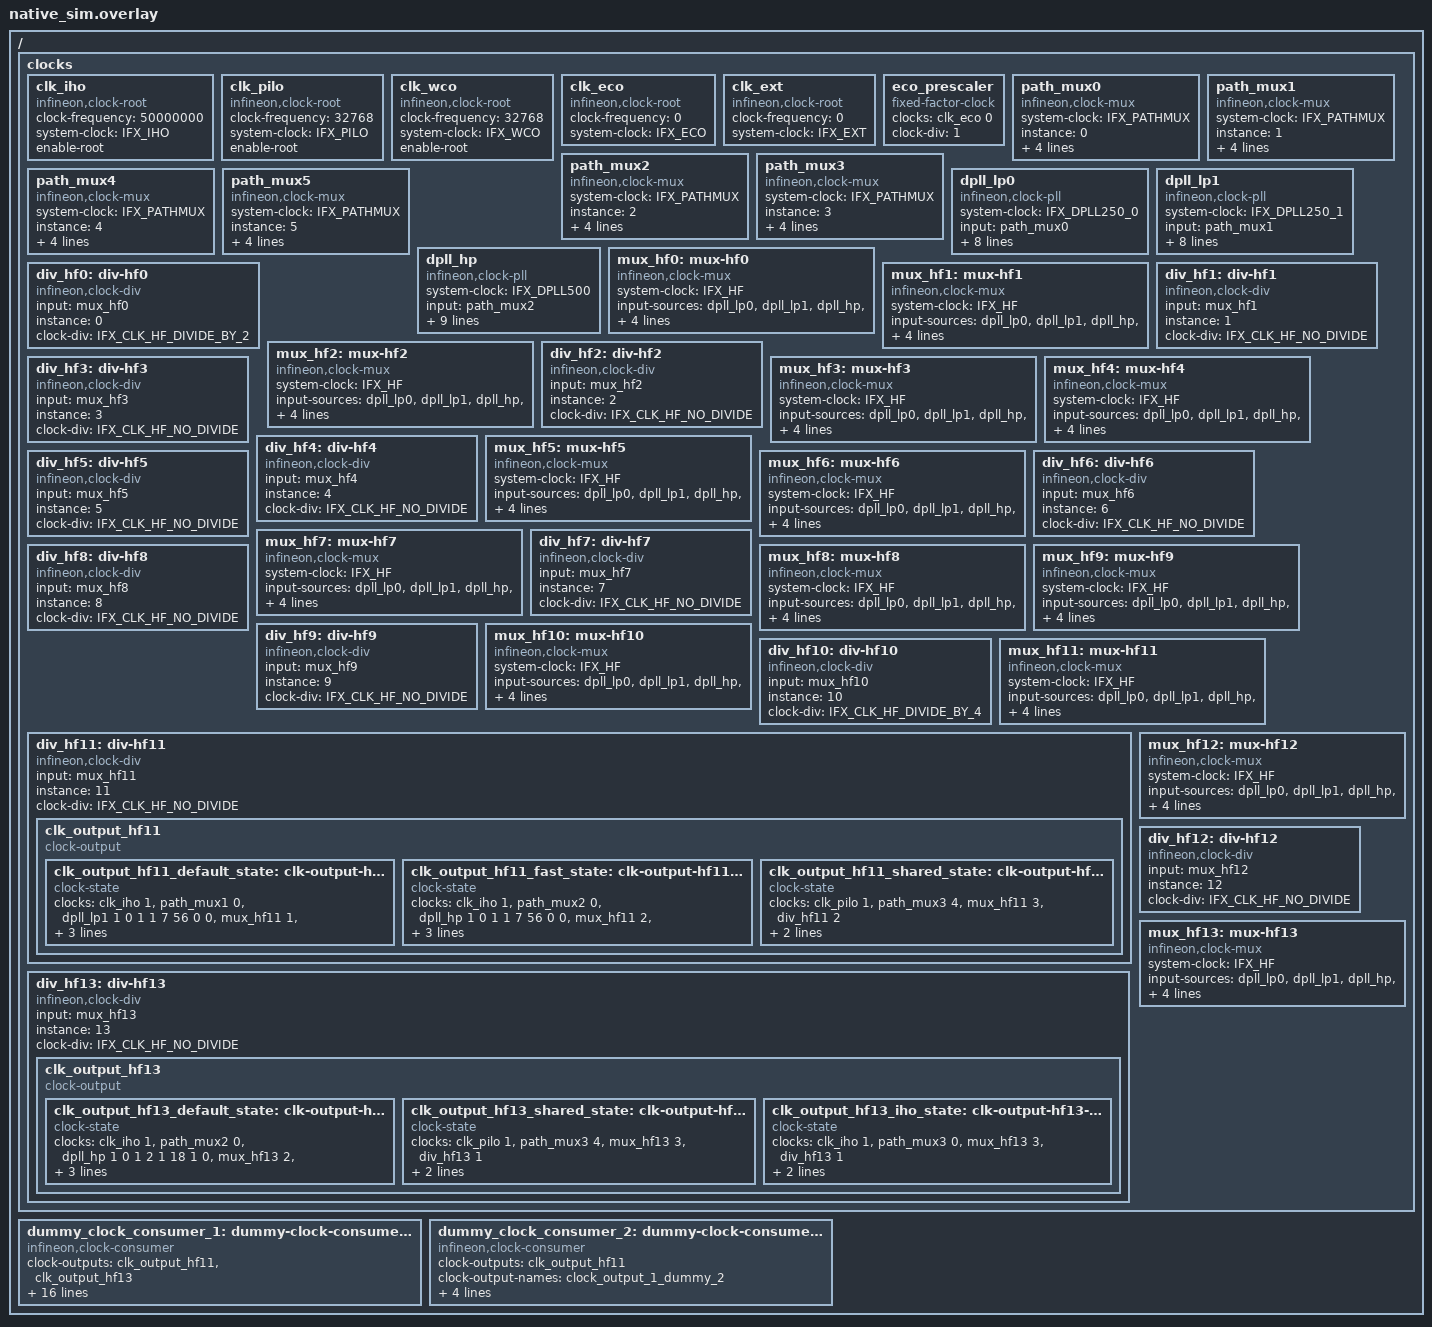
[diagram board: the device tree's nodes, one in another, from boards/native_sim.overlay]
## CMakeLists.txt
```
cmake_minimum_required(VERSION 3.20.0)
find_package(Zephyr REQUIRED HINTS $ENV{ZEPHYR_BASE})
project(pse84_m33_clock_management)

add_clock_management_header(include/infineon_clock_management_header.h)
zephyr_include_directories(include)

target_sources(app PRIVATE
    src/main.c
    drivers/infineon_clock_root.c
    drivers/infineon_clock_mux.c
    drivers/infineon_clock_pll.c
    drivers/infineon_clock_hf.c
    drivers/infineon_clock_div.c
    drivers/infineon_clock_consumer.c
)
```

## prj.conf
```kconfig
CONFIG_BUILD_OUTPUT_HEX=y
CONFIG_CLOCK_MANAGEMENT=y
CONFIG_CLOCK_MANAGEMENT_RUNTIME=y
CONFIG_NO_OPTIMIZATIONS=y
CONFIG_CLOCK_MANAGEMENT_SET_RATE=y
#CONFIG_INSTRUMENTATION_TRIGGER_FUNCTION="instrumentation_trigger"
#CONFIG_INSTRUMENTATION=y
#CONFIG_INSTRUMENTATION_MODE_CALLGRAPH=y
#CONFIG_INSTRUMENTATION_EXCLUDE_FILE_LIST="xip,bitmask,version,spi,i2c,adc,pwm,wdt,usb,mem,cy_crypto,cy_ble,cy_tcpwm,cy_adc,cy_dac,cy_smartio,cy_sdhc,cmsis,crypto,dma,cy_mpc,cy_ppc,cy_trigmux,qspi,bitarray"
#CONFIG_INSTRUMENTATION_EXCLUDE_FILE_LIST="isr_wrapper,xip,bitmask,version,spi,i2c,adc,pwm,wdt,usb,mem,cy_crypto,cy_ble,cy_tcpwm,cy_adc,cy_dac,cy_smartio,cy_sdhc,cmsis,crypto,dma,cy_mpc,cy_ppc,cy_trigmux,qspi,assert,bitarray"

#CONFIG_INSTRUMENTATION_EXCLUDE_FUNCTION_LIST="pm_device_runtime_is_enabled,device_is_ready,pm_device_is_busy,pm_device_wakeup_is_enabled,pm_device_action_run,main,k_busy_wait,sys_clock_elapsed,any_cpu_announcing,this_cpu_announcin,runq_bes,next_up,update_cache,sys_clock_cycle_get_32,arch_k_cycle_get_32,k_cycle_get_3,arch_irq_lock,arch_irq_unlock,timeout"
#CONFIG_INSTRUMENTATION_MODE_CALLGRAPH_TRACE_BUFFER_SIZE=32768
#CONFIG_INSTRUMENTATION_MODE_CALLGRAPH_BUFFER_OVERWRITE=y
#CONFIG_INSTRUMENTATION_STOPPER_FUNCTION="instrumentation_stopper"
#CONFIG_INSTRUMENTATION_DYNAMIC_TRIGGER=n
```

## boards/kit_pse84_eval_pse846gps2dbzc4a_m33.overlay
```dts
&clk_iho {
	#clock-cells = <1>;
	compatible = "infineon,clock-root";
};
&path_mux1 {
	#clock-cells = <1>;
	compatible = "infineon,clock-mux";
	input-sources = <&clk_iho>;
	/delete-property/ source-path;
};
&dpll_lp1 {
	#clock-cells = <7>;
	compatible = "infineon,clock-pll";
	clock-frequency = < 0x17d78400 >;
	feedback-div = < 0x38 >;
	output-div = < 0x1 >;
	fraction-div = < 0x0 >;
	input = <&path_mux1>;
	dco-mode-enable;
};
&clk_hf10 {
	#clock-cells = <2>;
	input-sources = <&dpll_lp1>;
	compatible = "infineon,clock-hf";
	clock-div = < 0x3 >;
	/delete-property/ source-path;
	clk_output_hf10: clk_output_hf10 {
		#clock-cells = <0>;
		compatible = "clock-output";
		clk_output_hf10_default_state: clk_output_hf10_default_state {
			compatible = "clock-state";
			clocks = <&clk_iho 0x2faf080>, <&path_mux1 0>, <&dpll_lp1 1 0 56 7 1 1 0>, <&clk_hf10 0 3>;
		};
	};
};
&scb2 {
	clock-outputs = <&clk_output_hf10>;
	clock-output-names = "uart_clk";
	clock-request-0 = <&clk_output_hf10_default_state>;
	clock-request-names = "default";
};
&scb4 {
	clock-outputs = <&clk_output_hf10>;
	clock-output-names = "uart_clk";
	clock-request-0 = <&clk_output_hf10_default_state>;
	clock-request-names = "default";
	status = "disabled";
};
```

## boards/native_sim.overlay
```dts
/ {
	/* Clock tree 1/3: roots and path muxes (the 3 /clocks blocks merge). */
	clocks {
		/*
		 * Root oscillator sources (TRM 21.3).
		 */

		/*
		 * Default clock source fixed frequency of 50MHz.
		 */
		clk_iho: clk_iho {
			compatible = "infineon,clock-root";
			#clock-cells = <1>;
			clock-frequency = <50000000>;
			system-clock = <IFX_IHO>;
			enable-root;
			status = "okay";
		};

		/*
		 * Precision-Low Power clock. 
		 */

		clk_pilo: clk_pilo {
			compatible = "infineon,clock-root";
			#clock-cells = <1>;
			clock-frequency = <32768>;
			system-clock = <IFX_PILO>;
			enable-root;
			status = "okay";
		};

		clk_wco: clk_wco {
			compatible = "infineon,clock-root";
			#clock-cells = <1>;
			clock-frequency = <32768>;
			system-clock = <IFX_WCO>;
			enable-root;
			status = "okay";
		};

		/*
		 * ECO and EXT_CLK need board components (a crystal or a driven
		 * clock pin)
		 */
		clk_eco: clk_eco {
			compatible = "infineon,clock-root";
			#clock-cells = <1>;
			clock-frequency = <0>;
			system-clock = <IFX_ECO>;
			status = "okay";
		};


		clk_ext: clk_ext {
			compatible = "infineon,clock-root";
			#clock-cells = <1>;
			clock-frequency = <0>;
			system-clock = <IFX_EXT>;
			status = "okay";
		};

		/*
		 * ECO prescaler (TRM 19.3.7); one of the CLK_LF source options.
		 * Disabled with its ECO parent: the generic fixed-factor
		 * producer would otherwise reference a clock object that a
		 * disabled clk_eco never emits.
		 */
		eco_prescaler: eco_prescaler {
			compatible = "fixed-factor-clock";
			#clock-cells = <0>;
			clocks = <&clk_eco 0>;
			clock-div = <1>;
			status = "okay";
		};

		/*
		 * Each clock path mux has a dsi mux which selects a 
		 * low frequency clock to clock a path.
		 * WCO - PILO
		 */
		/*
		 * Each clock-path has a mux that determines its source. 
		 * IHO - EXTCLK - ECO - DSI( WCO - PILO)
		 */
		path_mux0: path_mux0 {
			compatible = "infineon,clock-mux";
			#clock-cells = <1>;
			system-clock = < IFX_PATHMUX >;
			instance = <0>;
			input-sources = <&clk_iho &clk_ext &clk_eco &clk_wco &clk_pilo>;
			source-selects = < IFX_CAT1_CLKPATH_IN_IHO IFX_CAT1_CLKPATH_IN_EXT 
					   IFX_CAT1_CLKPATH_IN_ECO IFX_CAT1_CLKPATH_IN_WCO 
					   IFX_CAT1_CLKPATH_IN_PILO >;
			status = "okay";
		};

		path_mux1: path_mux1 {
			compatible = "infineon,clock-mux";
			#clock-cells = <1>;
			system-clock = < IFX_PATHMUX >;
			instance = <1>;
			input-sources = <&clk_iho &clk_ext &clk_eco &clk_wco &clk_pilo>;
			source-selects = < IFX_CAT1_CLKPATH_IN_IHO IFX_CAT1_CLKPATH_IN_EXT 
					   IFX_CAT1_CLKPATH_IN_ECO IFX_CAT1_CLKPATH_IN_WCO 
					   IFX_CAT1_CLKPATH_IN_PILO >;
			status = "okay";
		};

		path_mux2: path_mux2 {
			compatible = "infineon,clock-mux";
			#clock-cells = <1>;
			system-clock = < IFX_PATHMUX >;
			instance = <2>;
			input-sources = <&clk_iho &clk_ext &clk_eco &clk_wco &clk_pilo>;
			source-selects = < IFX_CAT1_CLKPATH_IN_IHO IFX_CAT1_CLKPATH_IN_EXT 
					   IFX_CAT1_CLKPATH_IN_ECO IFX_CAT1_CLKPATH_IN_WCO 
					   IFX_CAT1_CLKPATH_IN_PILO >;
			status = "okay";
		};

		path_mux3: path_mux3 {
			compatible = "infineon,clock-mux";
			#clock-cells = <1>;
			system-clock = < IFX_PATHMUX >;
			instance = <3>;
			input-sources = <&clk_iho &clk_ext &clk_eco &clk_wco &clk_pilo>;
			source-selects = < IFX_CAT1_CLKPATH_IN_IHO IFX_CAT1_CLKPATH_IN_EXT 
					   IFX_CAT1_CLKPATH_IN_ECO IFX_CAT1_CLKPATH_IN_WCO 
					   IFX_CAT1_CLKPATH_IN_PILO >;
			status = "okay";
		};

		path_mux4: path_mux4 {
			compatible = "infineon,clock-mux";
			#clock-cells = <1>;
			system-clock = < IFX_PATHMUX >;
			instance = <4>;
			input-sources = <&clk_iho &clk_ext &clk_eco &clk_wco &clk_pilo>;
			source-selects = < IFX_CAT1_CLKPATH_IN_IHO IFX_CAT1_CLKPATH_IN_EXT 
					   IFX_CAT1_CLKPATH_IN_ECO IFX_CAT1_CLKPATH_IN_WCO 
					   IFX_CAT1_CLKPATH_IN_PILO >;
			status = "okay";
		};

		path_mux5: path_mux5 {
			compatible = "infineon,clock-mux";
			#clock-cells = <1>;
			system-clock = < IFX_PATHMUX >;
			instance = <5>;
			input-sources = <&clk_iho &clk_ext &clk_eco &clk_wco &clk_pilo>;
			source-selects = < IFX_CAT1_CLKPATH_IN_IHO IFX_CAT1_CLKPATH_IN_EXT 
					   IFX_CAT1_CLKPATH_IN_ECO IFX_CAT1_CLKPATH_IN_WCO 
					   IFX_CAT1_CLKPATH_IN_PILO >;
			status = "okay";
		};
	};
};

/ {
	/* Clock tree 2/3: FLL, DPLLs, and the clk_hf roots. */
	clocks {
		/*
		 * The DPLL_i sits in CLK_PATH_i with path_mux_i as its reference.
		 */

		dpll_lp0: dpll_lp0 {
			compatible = "infineon,clock-pll";
			#clock-cells = < 8 >;  
			system-clock = < IFX_DPLL250_0 >;          
			input = < &path_mux0 >;
			bypass-sel = < 0 >;
			dco-mode-enable;
			output-div = < 1 >;
			reference-div = < 7 >; 
			feedback-div = < 56 >;
			fraction-enable = <0>;        
			fraction-div = < 0x0 >;            
			clock-frequency = < 400000000 >; 
			status = "okay";                            
		};

		dpll_lp1: dpll_lp1 {
			compatible = "infineon,clock-pll";
			#clock-cells = < 8 >;  
			system-clock = < IFX_DPLL250_1 >;          
			input = < &path_mux1 >;
			bypass-sel = < 0 >;
			dco-mode-enable;
			output-div = < 1 >;
			reference-div = < 7 >; 
			feedback-div = < 56 >;
			fraction-enable = <0>;       
			fraction-div = < 0x0 >;            
			clock-frequency = < 400000000 >; 
			status = "okay"; 
		};
		
		dpll_hp: dpll_hp {          
			compatible = "infineon,clock-pll";
			#clock-cells = < 8 >;
			system-clock = < IFX_DPLL500 >;
			input = < &path_mux2 >;
			bypass-sel = < 0 >;         
			div-p = < 0x0 >;                     
			div-n = < 0xb >;                    
			div-k = < 0x1 >;                     
			fraction-div = < 0x0 >;              
			freq-mode-sel = < 0x7 >;            
			flock-enable-threshold = < 0x3 >;    
			lf-beta-value = < 0x14 >;
			clock-frequency = < 0x11e1a300 >;
			status = "okay";         
		};

		/*
		 * Each high freq clock selects a clock path via ROOT_MUX
		 * and applies a predivider.
		 */


		mux_hf0: mux-hf0 {
			compatible = "infineon,clock-mux";
			#clock-cells = <1>;
			system-clock = < IFX_HF >;
			input-sources = < &dpll_lp0 &dpll_lp1 &dpll_hp &path_mux3 &path_mux4 &path_mux5 >;
			source-selects = < IFX_CLK_HF_IN_CLKPATH0 IFX_CLK_HF_IN_CLKPATH1 
					   IFX_CLK_HF_IN_CLKPATH2 IFX_CLK_HF_IN_CLKPATH3 
					   IFX_CLK_HF_IN_CLKPATH4 IFX_CLK_HF_IN_CLKPATH5 >;
			instance = <0>;
			status = "okay";
		};

		div_hf0: div-hf0 {
			compatible = "infineon,clock-div";
			#clock-cells = <1>;
			input = <&mux_hf0>;
			instance = < 0 >;
			clock-div = <IFX_CLK_HF_DIVIDE_BY_2>;
			status = "okay";
		};

		mux_hf1: mux-hf1 {
			compatible = "infineon,clock-mux";
			#clock-cells = <1>;
			system-clock = < IFX_HF >;
			input-sources = < &dpll_lp0 &dpll_lp1 &dpll_hp &path_mux3 &path_mux4 &path_mux5 >;
			source-selects = < IFX_CLK_HF_IN_CLKPATH0 IFX_CLK_HF_IN_CLKPATH1 
					   IFX_CLK_HF_IN_CLKPATH2 IFX_CLK_HF_IN_CLKPATH3 
					   IFX_CLK_HF_IN_CLKPATH4 IFX_CLK_HF_IN_CLKPATH5 >;
			instance = <1>;
			status = "okay";
		};

		div_hf1: div-hf1 {
			compatible = "infineon,clock-div";
			#clock-cells = <1>;
			input = <&mux_hf1>;
			instance = < 1 >;
			clock-div = <IFX_CLK_HF_NO_DIVIDE>;
			status = "okay";
		};

		mux_hf2: mux-hf2 {
			compatible = "infineon,clock-mux";
			#clock-cells = <1>;
			system-clock = < IFX_HF >;
			input-sources = < &dpll_lp0 &dpll_lp1 &dpll_hp &path_mux3 &path_mux4 &path_mux5 >;
			source-selects = < IFX_CLK_HF_IN_CLKPATH0 IFX_CLK_HF_IN_CLKPATH1 
					   IFX_CLK_HF_IN_CLKPATH2 IFX_CLK_HF_IN_CLKPATH3 
					   IFX_CLK_HF_IN_CLKPATH4 IFX_CLK_HF_IN_CLKPATH5 >;
			instance = <2>;
			status = "okay";
		};

		div_hf2: div-hf2 {
			compatible = "infineon,clock-div";
			#clock-cells = <1>;
			input = <&mux_hf2>;
			instance = < 2 >;
			clock-div = <IFX_CLK_HF_NO_DIVIDE>;
			status = "okay";
		};

		mux_hf3: mux-hf3 {
			compatible = "infineon,clock-mux";
			#clock-cells = <1>;
			system-clock = < IFX_HF >;
			input-sources = < &dpll_lp0 &dpll_lp1 &dpll_hp &path_mux3 &path_mux4 &path_mux5 >;
			source-selects = < IFX_CLK_HF_IN_CLKPATH0 IFX_CLK_HF_IN_CLKPATH1 
					   IFX_CLK_HF_IN_CLKPATH2 IFX_CLK_HF_IN_CLKPATH3 
					   IFX_CLK_HF_IN_CLKPATH4 IFX_CLK_HF_IN_CLKPATH5 >;
			instance = <3>;
			status = "okay";
		};

		div_hf3: div-hf3 {
			compatible = "infineon,clock-div";
			#clock-cells = <1>;
			input = <&mux_hf3>;
			instance = < 3 >;
			clock-div = <IFX_CLK_HF_NO_DIVIDE>;
			status = "okay";
		};

		mux_hf4: mux-hf4 {
			compatible = "infineon,clock-mux";
			#clock-cells = <1>;
			system-clock = < IFX_HF >;
			input-sources = < &dpll_lp0 &dpll_lp1 &dpll_hp &path_mux3 &path_mux4 &path_mux5 >;
			source-selects = < IFX_CLK_HF_IN_CLKPATH0 IFX_CLK_HF_IN_CLKPATH1 
					   IFX_CLK_HF_IN_CLKPATH2 IFX_CLK_HF_IN_CLKPATH3 
					   IFX_CLK_HF_IN_CLKPATH4 IFX_CLK_HF_IN_CLKPATH5 >;
			instance = <4>;
			status = "okay";
		};

		div_hf4: div-hf4 {
			compatible = "infineon,clock-div";
			#clock-cells = <1>;
			input = <&mux_hf4>;
			instance = < 4 >;
			clock-div = <IFX_CLK_HF_NO_DIVIDE>;
			status = "okay";
		};

		mux_hf5: mux-hf5 {
			compatible = "infineon,clock-mux";
			#clock-cells = <1>;
			system-clock = < IFX_HF >;
			input-sources = < &dpll_lp0 &dpll_lp1 &dpll_hp &path_mux3 &path_mux4 &path_mux5 >;
			source-selects = < IFX_CLK_HF_IN_CLKPATH0 IFX_CLK_HF_IN_CLKPATH1 
					   IFX_CLK_HF_IN_CLKPATH2 IFX_CLK_HF_IN_CLKPATH3 
					   IFX_CLK_HF_IN_CLKPATH4 IFX_CLK_HF_IN_CLKPATH5 >;
			instance = <5>;
			status = "okay";
		};

		div_hf5: div-hf5 {
			compatible = "infineon,clock-div";
			#clock-cells = <1>;
			input = <&mux_hf5>;
			instance = < 5 >;
			clock-div = <IFX_CLK_HF_NO_DIVIDE>;
			status = "okay";
		};

		mux_hf6: mux-hf6 {
			compatible = "infineon,clock-mux";
			#clock-cells = <1>;
			system-clock = < IFX_HF >;
			input-sources = < &dpll_lp0 &dpll_lp1 &dpll_hp &path_mux3 &path_mux4 &path_mux5 >;
			source-selects = < IFX_CLK_HF_IN_CLKPATH0 IFX_CLK_HF_IN_CLKPATH1 
					   IFX_CLK_HF_IN_CLKPATH2 IFX_CLK_HF_IN_CLKPATH3 
					   IFX_CLK_HF_IN_CLKPATH4 IFX_CLK_HF_IN_CLKPATH5 >;
			instance = <6>;
			status = "okay";
		};

		div_hf6: div-hf6 {
			compatible = "infineon,clock-div";
			#clock-cells = <1>;
			input = <&mux_hf6>;
			instance = < 6 >;
			clock-div = <IFX_CLK_HF_NO_DIVIDE>;
			status = "okay";
		};

		mux_hf7: mux-hf7 {
			compatible = "infineon,clock-mux";
			#clock-cells = <1>;
			system-clock = < IFX_HF >;
			input-sources = < &dpll_lp0 &dpll_lp1 &dpll_hp &path_mux3 &path_mux4 &path_mux5 >;
			source-selects = < IFX_CLK_HF_IN_CLKPATH0 IFX_CLK_HF_IN_CLKPATH1 
					   IFX_CLK_HF_IN_CLKPATH2 IFX_CLK_HF_IN_CLKPATH3 
					   IFX_CLK_HF_IN_CLKPATH4 IFX_CLK_HF_IN_CLKPATH5 >;
			instance = <7>;
			status = "okay";
		};

		div_hf7: div-hf7 {
			compatible = "infineon,clock-div";
			#clock-cells = <1>;
			input = <&mux_hf7>;
			instance = < 7 >;
			clock-div = <IFX_CLK_HF_NO_DIVIDE>;
			status = "okay";
		};

		mux_hf8: mux-hf8 {
			compatible = "infineon,clock-mux";
			#clock-cells = <1>;
			system-clock = < IFX_HF >;
			input-sources = < &dpll_lp0 &dpll_lp1 &dpll_hp &path_mux3 &path_mux4 &path_mux5 >;
			source-selects = < IFX_CLK_HF_IN_CLKPATH0 IFX_CLK_HF_IN_CLKPATH1 
					   IFX_CLK_HF_IN_CLKPATH2 IFX_CLK_HF_IN_CLKPATH3 
					   IFX_CLK_HF_IN_CLKPATH4 IFX_CLK_HF_IN_CLKPATH5 >;
			instance = <8>;
			status = "okay";
		};

		div_hf8: div-hf8 {
			compatible = "infineon,clock-div";
			#clock-cells = <1>;
			input = <&mux_hf8>;
			instance = < 8 >;
			clock-div = <IFX_CLK_HF_NO_DIVIDE>;
			status = "okay";
		};

		mux_hf9: mux-hf9 {
			compatible = "infineon,clock-mux";
			#clock-cells = <1>;
			system-clock = < IFX_HF >;
			input-sources = < &dpll_lp0 &dpll_lp1 &dpll_hp &path_mux3 &path_mux4 &path_mux5 >;
			source-selects = < IFX_CLK_HF_IN_CLKPATH0 IFX_CLK_HF_IN_CLKPATH1 
					   IFX_CLK_HF_IN_CLKPATH2 IFX_CLK_HF_IN_CLKPATH3 
					   IFX_CLK_HF_IN_CLKPATH4 IFX_CLK_HF_IN_CLKPATH5 >;
			instance = <9>;
			status = "okay";
		};

		div_hf9: div-hf9 {
			compatible = "infineon,clock-div";
			#clock-cells = <1>;
			input = <&mux_hf9>;
			instance = < 9 >;
			clock-div = <IFX_CLK_HF_NO_DIVIDE>;
			status = "okay";
		};

		mux_hf10: mux-hf10 {
			compatible = "infineon,clock-mux";
			#clock-cells = <1>;
			system-clock = < IFX_HF >;
			input-sources = < &dpll_lp0 &dpll_lp1 &dpll_hp &path_mux3 &path_mux4 &path_mux5 >;
			source-selects = < IFX_CLK_HF_IN_CLKPATH0 IFX_CLK_HF_IN_CLKPATH1 
					   IFX_CLK_HF_IN_CLKPATH2 IFX_CLK_HF_IN_CLKPATH3 
					   IFX_CLK_HF_IN_CLKPATH4 IFX_CLK_HF_IN_CLKPATH5 >;
			instance = <10>;
			status = "okay";
		};

		div_hf10: div-hf10 {
			compatible = "infineon,clock-div";
			#clock-cells = <1>;
			input = <&mux_hf10>;
			instance = < 10 >;
			clock-div = <IFX_CLK_HF_DIVIDE_BY_4>;
			status = "okay";
		};

		mux_hf11: mux-hf11 {
			compatible = "infineon,clock-mux";
			#clock-cells = <1>;
			system-clock = < IFX_HF >;
			input-sources = < &dpll_lp0 &dpll_lp1 &dpll_hp &path_mux3 &path_mux4 &path_mux5 >;
			source-selects = < IFX_CLK_HF_IN_CLKPATH0 IFX_CLK_HF_IN_CLKPATH1 
					   IFX_CLK_HF_IN_CLKPATH2 IFX_CLK_HF_IN_CLKPATH3 
					   IFX_CLK_HF_IN_CLKPATH4 IFX_CLK_HF_IN_CLKPATH5 >;
			instance = <11>;
			status = "okay";
		};

		div_hf11: div-hf11 {
			compatible = "infineon,clock-div";
			#clock-cells = <1>;
			input = <&mux_hf11>;
			instance = < 11 >;
			clock-div = <IFX_CLK_HF_NO_DIVIDE>;
			status = "okay";
		};

		mux_hf12: mux-hf12 {
			compatible = "infineon,clock-mux";
			#clock-cells = <1>;
			system-clock = < IFX_HF >;
			input-sources = < &dpll_lp0 &dpll_lp1 &dpll_hp &path_mux3 &path_mux4 &path_mux5 >;
			source-selects = < IFX_CLK_HF_IN_CLKPATH0 IFX_CLK_HF_IN_CLKPATH1 
					   IFX_CLK_HF_IN_CLKPATH2 IFX_CLK_HF_IN_CLKPATH3 
					   IFX_CLK_HF_IN_CLKPATH4 IFX_CLK_HF_IN_CLKPATH5 >;
			instance = <12>;
			status = "okay";
		};

		div_hf12: div-hf12 {
			compatible = "infineon,clock-div";
			#clock-cells = <1>;
			input = <&mux_hf12>;
			instance = < 12 >;
			clock-div = <IFX_CLK_HF_NO_DIVIDE>;
			status = "okay";
		};

		mux_hf13: mux-hf13 {
			compatible = "infineon,clock-mux";
			#clock-cells = <1>;
			system-clock = < IFX_HF >;
			input-sources = < &dpll_lp0 &dpll_lp1 &dpll_hp &path_mux3 &path_mux4 &path_mux5 >;
			source-selects = < IFX_CLK_HF_IN_CLKPATH0 IFX_CLK_HF_IN_CLKPATH1 
					   IFX_CLK_HF_IN_CLKPATH2 IFX_CLK_HF_IN_CLKPATH3 
					   IFX_CLK_HF_IN_CLKPATH4 IFX_CLK_HF_IN_CLKPATH5 >;
			instance = <13>;
			status = "okay";
		};

		div_hf13: div-hf13 {
			compatible = "infineon,clock-div";
			#clock-cells = <1>;
			input = <&mux_hf13>;
			instance = < 13 >;
			clock-div = <IFX_CLK_HF_NO_DIVIDE>;
			status = "okay";
		};

	};
};

/{
	dummy_clock_consumer_1: dummy-clock-consumer-1{
		compatible = "infineon,clock-consumer";
		clock-outputs = <&clk_output_hf11 &clk_output_hf13>;
		clock-output-names = "clock_output_1_dummy_1", "clock_output_2_dummy_1";
		clock-request-0 = <&clk_output_hf11_default_state &clk_output_hf13_default_state>;
		clock-request-1 = <&clk_output_hf11_shared_state &clk_output_hf13_shared_state>;
		clock-request-2 = <&clk_output_hf11_fast_state &clk_output_hf13_default_state>;
		clock-request-3 = <&clk_output_hf13_iho_state>;
		clock-request-4 = <&clk_output_hf11_default_state &clk_output_hf11_shared_state &clk_output_hf11_fast_state>;
		clock-request-names = "default", "shared", "fast", "iho", "all";
	};

	dummy_clock_consumer_2: dummy-clock-consumer-2{
		compatible = "infineon,clock-consumer";
		clock-outputs = <&clk_output_hf11>;
		clock-output-names = "clock_output_1_dummy_2";
		clock-request-0 = <&clk_output_hf11_default_state>;
		clock-request-1 = <&clk_output_hf11_fast_state>;
		clock-request-2 = <&clk_output_hf11_shared_state>;
		clock-request-names = "default", "fast", "shared";
	};
};

&div_hf11 {
	clk_output_hf11: clk_output_hf11 {
		#clock-cells = <0>;
		compatible = "clock-output";
		clk_output_hf11_default_state: clk-output-hf11-default-state {
			compatible = "clock-state";
			clocks = <&clk_iho 1>, <&path_mux1 0>, <&dpll_lp1 1 0 1 1 7 56 0 0>, <&mux_hf11 1 >, <&div_hf11 3>;
			clock-frequency = <133333330>;
			rank = < 2 >;
		};
		clk_output_hf11_fast_state: clk-output-hf11-fast-state {
			compatible = "clock-state";
			clocks = <&clk_iho 1>, <&path_mux2 0>, <&dpll_hp 1 0 1 1 7 56 0 0>, <&mux_hf11 2>, <&div_hf11 1>;
			clock-frequency = <450000000>;
			rank = < 0 >;
		};
		clk_output_hf11_shared_state: clk-output-hf11-shared-state {
			compatible = "clock-state";
			clocks = <&clk_pilo 1>, <&path_mux3 4>, <&mux_hf11 3>, <&div_hf11 2>;
			clock-frequency = <16384>;
			rank = < 1 >;
		};
	};
};

&div_hf13 {
	clk_output_hf13: clk_output_hf13 {
		#clock-cells = <0>;
		compatible = "clock-output";
		clk_output_hf13_default_state: clk-output-hf13-default-state {
			compatible = "clock-state";
			clocks = <&clk_iho 1>, <&path_mux2 0>, <&dpll_hp 1 0 1 2 1 18 1 0>, <&mux_hf13 2 >, <&div_hf13 2>;
			clock-frequency = <225000000>;
			rank = < 0 >;
		};
		clk_output_hf13_shared_state: clk-output-hf13-shared-state {
			compatible = "clock-state";
			clocks = <&clk_pilo 1>, <&path_mux3 4>, <&mux_hf13 3>, <&div_hf13 1>;
			clock-frequency = <32768>;
			rank = < 0 >;
		};
		clk_output_hf13_iho_state: clk-output-hf13-iho-state {
			compatible = "clock-state";
			clocks = <&clk_iho 1>, <&path_mux3 0>, <&mux_hf13 3>, <&div_hf13 1>;
			clock-frequency = <50000000>;
			rank = < 0 >;
		};
	};
};
```

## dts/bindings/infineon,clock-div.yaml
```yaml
# Copyright (c) 2025 Cypress Semiconductor Corporation (an Infineon company) or
# an affiliate of Cypress Semiconductor Corporation
#
# SPDX-License-Identifier: Apache-2.0

description: Generic fixed-rate clock provider

compatible: "infineon,clock-div"

include: fixed-factor-clock.yaml

properties:
  instance:
    type: int
    required: true
    description: |
      Instance of a given clock type.
      clk_hf0   : instance = <0>

  input:
    type: phandle
    required: true
    description: Clock-path multiplexer supplying the DPLL reference.

    
  "#clock-cells":
    type: int
    const: 1

clock-cells:
  - div
```

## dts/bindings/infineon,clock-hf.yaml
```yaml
# Copyright (c) 2025 Cypress Semiconductor Corporation (an Infineon company) or
# an affiliate of Cypress Semiconductor Corporation
#
# SPDX-License-Identifier: Apache-2.0

description: Generic fixed-rate clock provider

compatible: "infineon,clock-hf"

include: fixed-factor-clock.yaml

properties:
  system-clock:
    type: int
    description: |
      The type of clock (refer to include/.../dt-bindings/clock/ifx_clock_source_common.h):
      path_mux5 : system-clock = <IFX_PATHMUX>
      clk_hf0   : system-clock = <IFX_HF>

  instance:
    type: int
    required: true
    description: |
      Instance of a given clock type.
      path_mux5 : instance = <5>
      clk_hf0   : instance = <0>

  input-sources:
    type: phandles
    required: true
    description: List of clock path sources

  source-selects:
    type: array
    required: true
    description: |
      Hardware source identifier for each entry in
      input-sources, in the same order. Provides the index-to-enum mapping
      the generic clock-mux binding lacks.

  "#clock-cells":
    const: 2

clock-cells:
  - path_sel
  - div_value

  
```

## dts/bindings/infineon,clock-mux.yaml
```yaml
description: Infineon CAT1 Clock Root Mux
compatible: "infineon,clock-mux"

include: [clock-node.yaml]

properties:

  system-clock:
    type: int
    description: |
      The type of clock (refer to include/.../dt-bindings/clock/ifx_clock_source_common.h):

  instance:
    type: int
    required: true
    description: |
      Instance (correlated to path number) of a given high frequency mux.

  input-sources:
    type: phandles
    required: true
    description: List of clock path sources

  source-selects:
    type: array
    required: true
    description: |
      Hardware source identifier for each entry in
      input-sources, in the same order. Provides the index-to-enum mapping
      the generic clock-mux binding lacks.

  "#clock-cells":
    const: 1

clock-cells:
  - mux
```

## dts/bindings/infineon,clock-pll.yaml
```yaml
# Copyright (c) 2025 Cypress Semiconductor Corporation (an Infineon company) or
# an affiliate of Cypress Semiconductor Corporation
#
# SPDX-License-Identifier: Apache-2.0

description: Generic fixed-rate clock provider

compatible: "infineon,clock-pll"

include: fixed-factor-clock.yaml

properties:
  system-clock:
    type: int
    required: true
    description: |
      Clock producer identifier
      clk_iho  : system-clock = <IFX_IHO>
      clk_pilo : system-clock = <IFX_PILO>

  input:
    type: phandle
    required: true
    description: Clock-path multiplexer supplying the DPLL reference.

  clock-frequency:
    type: int
    description: output clock frequency (Hz)
    required: true
  
  enable: 
    type: int
    
  bypass-sel:
    type: int

  dco-mode-enable:
    type: boolean

  output-div:
    type: int
  
  reference-div:
    type: int

  feedback-div:
    type: int

  fraction-enable:
    type: int

  fraction-div:
    type: int
    description: Sets the frac_div value in f_OUT = f_REF(N + FRAC_DIV/2^24)

  div-p:
    type: int

  div-n:
    type: int

  div-k:
    type: int

  freq-mode-sel:
    type: int

  flock-enable-threshold:
    type: int

  lf-beta-value:
    type: int

  "#clock-cells":
    type: int
    const: 8

clock-cells:
  - enable
  - bypass
  - dco
  - output
  - reference
  - feedback
  - fraction
  - fraction-div
```

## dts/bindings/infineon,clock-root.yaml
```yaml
# Copyright (c) 2025 Cypress Semiconductor Corporation (an Infineon company) or
# an affiliate of Cypress Semiconductor Corporation
#
# SPDX-License-Identifier: Apache-2.0

description: Generic fixed-rate clock provider

compatible: "infineon,clock-root"

include: fixed-clock.yaml

properties:
  system-clock:
    type: int
    required: true
    description: |
      The type of clock (refer to include/.../dt-bindings/clock/ifx_clock_source_common.h):
      clk_iho  : system-clock = <IFX_IHO>
      clk_pilo : system-clock = <IFX_PILO>
  
  enable-root:
    type: boolean
    description: Enable oscillator 

  "#clock-cells":
    const: 1

clock-cells:
  - root_enable
```

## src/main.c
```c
#include <zephyr/drivers/clock_management.h>
#include <zephyr/sys/sys_io.h>
#include <cy_sysclk.h>
#include <zephyr/device.h>
#include <zephyr/kernel.h>

#define DUMMY_CONSUMER_1 DT_NODELABEL(dummy_clock_consumer_1)
#define DUMMY_CONSUMER_2 DT_NODELABEL(dummy_clock_consumer_2)
#define UART_CONSUMER DT_NODELABEL(dummy_clock_consumer_3)

static const struct device *dummy_device_1 = DEVICE_DT_GET(DUMMY_CONSUMER_1);
static const struct device *dummy_device_2 = DEVICE_DT_GET(DUMMY_CONSUMER_2);
static const struct device *uart_device = DEVICE_DT_GET(UART_CONSUMER);

static const struct clk *iho_producer = CLOCK_DT_GET(DT_NODELABEL(clk_iho));
static const struct clk *pll_hp = CLOCK_DT_GET(DT_NODELABEL(dpll_hp));
static const struct clk *pll_lp1 = CLOCK_DT_GET(DT_NODELABEL(dpll_lp1));
static const struct clk *pll_lp0 = CLOCK_DT_GET(DT_NODELABEL(dpll_lp0));

static const struct clk *p_mux1 = CLOCK_DT_GET(DT_NODELABEL(path_mux1));



static const clock_request_t default_req_dummy_1 = CLOCK_MANAGEMENT_DT_GET_REQUEST(DUMMY_CONSUMER_1, default);
static const clock_request_t default_req_dummy_2 = CLOCK_MANAGEMENT_DT_GET_REQUEST(DUMMY_CONSUMER_2, default);
static const clock_request_t default_req_uart = CLOCK_MANAGEMENT_DT_GET_REQUEST(UART_CONSUMER, default);
//static const clock_output_t uart_clock = CLOCK_MANAGEMENT_DT_GET_OUTPUT_BY_NAME(UART_CONSUMER, uart_clk);

static const clock_request_t failed_req_dummy_2 = CLOCK_MANAGEMENT_DT_GET_REQUEST(DUMMY_CONSUMER_2, failed);

static const clock_request_t fast_req_dummy_2 = CLOCK_MANAGEMENT_DT_GET_REQUEST(DUMMY_CONSUMER_2, fast);

static const clock_request_t shared_req_dummy_1 = CLOCK_MANAGEMENT_DT_GET_REQUEST(DUMMY_CONSUMER_1, shared);
static const clock_request_t shared_req_dummy_2 = CLOCK_MANAGEMENT_DT_GET_REQUEST(DUMMY_CONSUMER_2, shared);

//static const clock_request_t random_req_dummy_1 = CLOCK_MANAGEMENT_DT_GET_REQUEST(DUMMY_CONSUMER_1, random);

static const clock_request_t all_req_dummy_1 = CLOCK_MANAGEMENT_DT_GET_REQUEST(DUMMY_CONSUMER_1, all);

static const clock_output_t dummy_1_clk_1 = CLOCK_MANAGEMENT_DT_GET_OUTPUT_BY_NAME(DUMMY_CONSUMER_1, clock_output_1_dummy_1);
static const clock_output_t dummy_1_clk_2 = CLOCK_MANAGEMENT_DT_GET_OUTPUT_BY_NAME(DUMMY_CONSUMER_1, clock_output_2_dummy_1);
static const clock_output_t dummy_2_clk_1 = CLOCK_MANAGEMENT_DT_GET_OUTPUT_BY_NAME(DUMMY_CONSUMER_2, clock_output_1_dummy_2);



struct freq_group {
	const uint32_t *freqs;
	size_t len;
};

struct ifx_clock_consumer_config {
	const uint32_t instance;
	const struct clock_management_data *clk_mgmt;
	const struct freq_group *freq_groups;
	const size_t num_groups;
};

int main(void){
	int ret = -1;
	const struct ifx_clock_consumer_config *config_dummy_1 = dummy_device_1->config;
	const struct ifx_clock_consumer_config *config_dummy_2 = dummy_device_2->config;
	const struct ifx_clock_consumer_config *config_uart = uart_device->config;
	uint8_t activeRequest_dummy_1;
	uint8_t activeRequest_dummy_2;
	ret = clock_management_request_state(config_uart->clk_mgmt, default_req_uart);
	clock_freq_t rate_iho = iho_producer->subsys_data->rate;
	/*LOCKING TEST
	*/
	/*
	ret = clock_management_request_state(config_dummy_1->clk_mgmt,default_req_dummy_1);
	ret = clock_management_request_state(config_dummy_2->clk_mgmt,default_req_dummy_2);
	ret = clock_management_lock(config_dummy_1->clk_mgmt,dummy_1_clk_1);
	ret = clock_management_request_state(config_dummy_1->clk_mgmt,all_req_dummy_1);


	ret = clock_management_request_state(config_dummy_2->clk_mgmt,fast_req_dummy_2);
*/


	/*ON TEST

	ret = clock_management_request_state(config_dummy_1->clk_mgmt,default_req_dummy_1);
	if (ret<0){
		return 0;
	}
	ret = clock_management_on(config_dummy_1->clk_mgmt, dummy_1_clk_2);
	uint8_t iho_counter = iho_producer->subsys_data->usage_cnt;
	uint8_t pll_hp_counter = pll_hp->subsys_data->usage_cnt;
	uint8_t pll_lp1_counter = pll_lp1->subsys_data->usage_cnt;
	uint8_t pll_lp0_counter = pll_lp0->subsys_data->usage_cnt;
	uint8_t mux_counter = p_mux1->subsys_data->usage_cnt;
	printk("%d", iho_counter);
	if (iho_counter<0){
		return 0;
	}
	*/
	ret = clock_management_request_state(config_dummy_1->clk_mgmt,default_req_dummy_1);
	if (ret<0){
		return 0;
	}
	
	ret = clock_management_request_state(config_dummy_2->clk_mgmt,default_req_dummy_2);
	if (ret<0){
		return 0;
	}
	
	ret = clock_management_on(config_dummy_1->clk_mgmt, dummy_1_clk_1);
	ret = clock_management_on(config_dummy_1->clk_mgmt, dummy_1_clk_2);
	
	ret = clock_management_on(config_dummy_2->clk_mgmt, dummy_2_clk_1);

	ret = clock_management_request_state(config_dummy_2->clk_mgmt,failed_req_dummy_2);
	/*
	clock_freq_t freq = 100000000;
	ret = clock_management_req_rate(config_dummy_1->clk_mgmt, dummy_1_clk_2, freq);
	if (ret<0){
		return 0;
	}
	*/

/*SHARED_TEST

	ret = clock_management_request_state(config_dummy_2->clk_mgmt,shared_req_dummy_2);
	if (ret<0){
		return 0;
	}
	activeRequest_dummy_1 =  *(config_dummy_1->clk_mgmt->active_request);
	activeRequest_dummy_2 = *(config_dummy_2->clk_mgmt->active_request);
	printf("%d\n",activeRequest_dummy_1);
	printf("%d\n",activeRequest_dummy_2);
	
	ret = clock_management_request_state(config_dummy_1->clk_mgmt,shared_req_dummy_1);
	if (ret<0){
		return 0;
	}
	activeRequest_dummy_1 =  *(config_dummy_1->clk_mgmt->active_request);
	activeRequest_dummy_2 = *(config_dummy_2->clk_mgmt->active_request);
	printf("%d\n",activeRequest_dummy_1);
	printf("%d\n",activeRequest_dummy_2);

	ret = clock_management_request_state(config_dummy_1->clk_mgmt,random_req_dummy_1);
	if (ret<0){
		return 0;
	}
	activeRequest_dummy_1 =  *(config_dummy_1->clk_mgmt->active_request);
	activeRequest_dummy_2 = *(config_dummy_2->clk_mgmt->active_request);
	printf("%d\n",activeRequest_dummy_1);
	printf("%d\n",activeRequest_dummy_2);

*/
	while(1){
		
	}
	return 0;
}
```

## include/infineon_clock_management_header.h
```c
#ifndef CLOCK_IFX_DATA_H
#define CLOCK_IFX_DATA_H

#include <zephyr/devicetree.h>
#include <stdint.h>

typedef struct{
    bool pll_enable;
    uint8_t bypass_sel;
    uint32_t fb_div;
    uint32_t ref_div;
    uint32_t output_div;
    bool dco_mode;
    uint32_t fraction_enable;
    uint32_t fraction_div;
}ifx_dpll_lp_spec;

typedef struct{
    uint8_t selector;
    uint32_t clock_division;
}ifx_hf_clock_spec;

/*
ROOT
*/
#define Z_CLOCK_MANAGEMENT_DATA_DEFINE_infineon_clock_root(node_id, prop, idx) 	\
	static const bool Z_CLOCK_DATA_##node_id##_##idx =                      \
    DT_PHA_BY_IDX(node_id, prop, idx, root_enable);                             \
/*Pointer to the specifier value. This pointer is passed to the APIS.*/
#define Z_CLOCK_MANAGEMENT_DATA_GET_infineon_clock_root(node_id, prop, idx) 	\
	((void *)&Z_CLOCK_DATA_##node_id##_##idx)

/*Macro that stores the specifier value for being used by the framework.
MUX
*/
#define Z_CLOCK_MANAGEMENT_DATA_DEFINE_infineon_clock_mux(node_id, prop, idx) 	\
	static const uint32_t Z_CLOCK_DATA_##node_id##_##idx = 			            \
	DT_PHA_BY_IDX(node_id, prop, idx, mux);
/*Pointer to the specifier value. This pointer is passed to the APIS.*/
#define Z_CLOCK_MANAGEMENT_DATA_GET_infineon_clock_mux(node_id, prop, idx) 	    \
	((void *)&Z_CLOCK_DATA_##node_id##_##idx)
/*
DIVIDER
*/
#define Z_CLOCK_MANAGEMENT_DATA_DEFINE_infineon_clock_div(node_id, prop, idx) 	\
	static const uint32_t Z_CLOCK_DATA_##node_id##_##idx = 			            \
	DT_PHA_BY_IDX(node_id, prop, idx, div);
#define Z_CLOCK_MANAGEMENT_DATA_GET_infineon_clock_div(node_id, prop, idx) 	    \
	((void *)&Z_CLOCK_DATA_##node_id##_##idx)
/*
PLL
*/
#define Z_CLOCK_MANAGEMENT_DATA_DEFINE_infineon_clock_pll(node_id, prop, idx) 	\
	static const ifx_dpll_lp_spec Z_CLOCK_DATA_##node_id##_##idx = {            \
        .pll_enable = DT_PHA_BY_IDX(node_id, prop, idx, enable),                \
        .bypass_sel = DT_PHA_BY_IDX(node_id, prop, idx, bypass),          	    \
        .fb_div     = DT_PHA_BY_IDX(node_id, prop, idx, feedback),        	    \
        .ref_div    = DT_PHA_BY_IDX(node_id, prop, idx, reference),       	    \
        .output_div = DT_PHA_BY_IDX(node_id, prop, idx, output),          	    \
        .dco_mode   = (bool)DT_PHA_BY_IDX(node_id, prop, idx, dco),            	\
        .fraction_enable = DT_PHA_BY_IDX(node_id, prop, idx, fraction),             \
        .fraction_div = DT_PHA_BY_IDX(node_id, prop, idx, fraction_div),     	\
    	};
#define Z_CLOCK_MANAGEMENT_DATA_GET_infineon_clock_pll(node_id, prop, idx) 	    \
	((void *)&Z_CLOCK_DATA_##node_id##_##idx)
/*
HIGH FREQU
*/
#define Z_CLOCK_MANAGEMENT_DATA_DEFINE_infineon_clock_hf(node_id, prop, idx) 	\
	static const ifx_hf_clock_spec Z_CLOCK_DATA_##node_id##_##idx = {           \
        .selector = DT_PHA_BY_IDX(node_id, prop, idx, path_sel),                \
        .clock_division = DT_PHA_BY_IDX(node_id, prop, idx, div_value),         \
    };
/*Pointer to the specifier value. This pointer is passed to the APIS.*/
#define Z_CLOCK_MANAGEMENT_DATA_GET_infineon_clock_hf(node_id, prop, idx) 	    \
	((void *)&Z_CLOCK_DATA_##node_id##_##idx)

#endif
```

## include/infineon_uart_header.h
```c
#ifndef INFINEON_UART_HEADER_H_
#define INFINEON_UART_HEADER_H_

#include <zephyr/device.h>

#ifdef __cplusplus
extern "C" {
#endif

/**
 * @brief Get the clock_output_t handle associated with this UART device.
 *
 * @param dev UART device instance.
 * @return clock_output_t index into the device's clock_management_data.
 */
uint8_t ifx_cat1_uart_get_macro_val(const struct device *dev);

/**
 * @brief Enable the clock output (and its parent producers) for this UART.
 *
 * @param dev UART device instance.
 * @return 0 on success, negative errno on failure.
 */
int ifx_cat1_uart_clk_on(const struct device *dev);

/**
 * @brief Disable the clock output (and its parent producers) for this UART.
 *
 * @param dev UART device instance.
 * @return 0 on success, negative errno on failure.
 */
int ifx_cat1_uart_clk_off(const struct device *dev);

#ifdef __cplusplus
}
#endif

#endif /* INFINEON_UART_HEADER_H_ */
```
